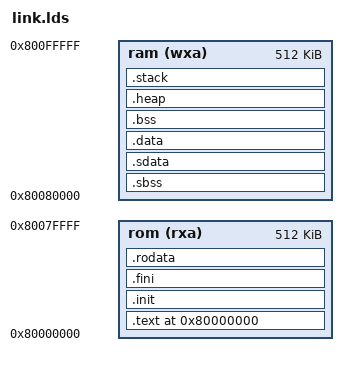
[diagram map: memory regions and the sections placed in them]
OUTPUT_ARCH( "riscv" )

_STACK_SIZE = DEFINED(_STACK_SIZE) ? _STACK_SIZE : 0x1000;
_HEAP_SIZE = DEFINED(_HEAP_SIZE) ? _HEAP_SIZE : 0x1000;

/*****************************************************************************
 * Define memory layout
 ****************************************************************************/
MEMORY
{
	/* Fake ROM area */
	rom (rxa) : ORIGIN = 0x80000000, LENGTH = 512K
	ram (wxa) : ORIGIN = 0x80080000, LENGTH = 512K
}


/* Specify the default entry point to the program */

ENTRY(_boot)

/*****************************************************************************
 * Define the sections, and where they are mapped in memory 
 ****************************************************************************/

SECTIONS
{
    . = 0x80000000;
	
	.text : {
	   *boot.o(.text);
		*(.text);
		*(.text.*);
	} > rom

   .init : {
	   KEEP (*(.init))
	} > rom
	
	.fini : {
       KEEP (*(.fini))
    } > rom

	.rodata : {
       __rodata_start = .;
       *(.rodata)
       *(.rodata.*)
       *(.gnu.linkonce.r.*)
       __rodata_end = .;
	} > rom

	.sbss : {
	   __sbss_start = .;
	   *(.sbss)
	   *(.sbss.*)
	   *(.gnu.linkonce.sb.*)
	   __sbss_end = .;
	} > ram

	.sdata : {
        _gp = . + 0x800;
        *(.srodata.cst16) *(.srodata.cst8) *(.srodata.cst4) *(.srodata.cst2) *(.srodata*)
        *(.sdata .sdata.* .gnu.linkonce.s.*)
     }	> ram

	.data : {
	   . = ALIGN(4);
	   __data_start = .;
	   *(.data)
	   *(.data.*)
	   *(.gnu.linkonce.d.*)
	   __data_end = .;
	} > ram

	.bss : {
       . = ALIGN(4);
       __bss_start = .;
       *(.bss)
       *(.bss.*)
       *(.gnu.linkonce.b.*)
       *(COMMON)
       . = ALIGN(4);
       __bss_end = .;
    } > ram

	/* Generate Stack and Heap definitions */

    .heap : {
       . = ALIGN(4);
       _heap = .;
       _heap_start = .;
       . += _HEAP_SIZE;
       _heap_end = .;
    } > ram

    .stack : {
       _stack_end = .;
       . += _STACK_SIZE;
       . = ALIGN(4);
       _stack = .;
       __stack = _stack;
    } > ram
    
    _end = .;
}
